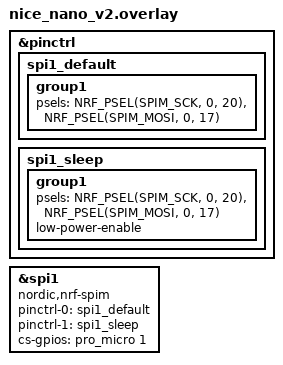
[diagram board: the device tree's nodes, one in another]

/**
 * Generated by Shield Wizard for ZMK
 * Applies to shield "bcp_shell_v3_dongle" with board "nice_nano_v2" only
 */

//
// ======== spi1 ========
//

// pin control for spi1
// - SCK on D3
// - MOSI on D2
&pinctrl {
    /* configuration for spi1 device, default state */
    spi1_default: spi1_default {
        group1 {
            psels = <NRF_PSEL(SPIM_SCK, 0, 20)>,
                    <NRF_PSEL(SPIM_MOSI, 0, 17)>;
        };
    };
    /* configuration for spi1 device, sleep state */
    spi1_sleep: spi1_sleep {
        group1 {
            psels = <NRF_PSEL(SPIM_SCK, 0, 20)>,
                    <NRF_PSEL(SPIM_MOSI, 0, 17)>;
            low-power-enable;
        };
    };
};
&spi1 {
  compatible = "nordic,nrf-spim";
  status = "okay";
  pinctrl-0 = <&spi1_default>;
  pinctrl-1 = <&spi1_sleep>;
  pinctrl-names = "default", "sleep";
};

// devices on spi1

// CS pins for devices on spi1
&spi1 {
    cs-gpios = <&pro_micro 1 GPIO_ACTIVE_HIGH>;
};

// Label spi1 as nice_view_spi,
// The actual device node is defined in the `nice_view` shield.
nice_view_spi: &spi1 { };
